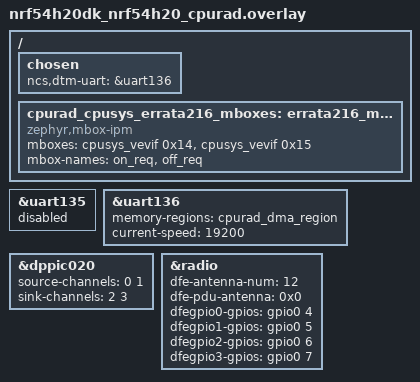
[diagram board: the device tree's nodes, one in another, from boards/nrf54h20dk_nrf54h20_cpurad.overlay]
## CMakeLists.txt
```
#
# Copyright (c) 2020 Nordic Semiconductor
#
# SPDX-License-Identifier: LicenseRef-Nordic-5-Clause
#
cmake_minimum_required(VERSION 3.20.0)

find_package(Zephyr REQUIRED HINTS $ENV{ZEPHYR_BASE})
project(NONE)

target_include_directories(app PRIVATE ./src)

target_sources_ifndef(CONFIG_DTM_TRANSPORT_HCI app PRIVATE
  src/transport/dtm_uart_twowire.c
  src/transport/dtm_uart_wait.c
)

target_sources_ifdef(CONFIG_DTM_TRANSPORT_HCI app PRIVATE src/transport/dtm_hci.c)

if(CONFIG_DTM_TRANSPORT_HCI AND "${BOARD}" STREQUAL "nrf5340dk")
  target_sources(app PRIVATE src/transport/hci_uart_remote.c)
  target_include_directories(app PRIVATE ./rpc)
else()
  target_sources_ifdef(CONFIG_DTM_TRANSPORT_HCI app PRIVATE src/transport/hci_uart.c)
endif()

# NORDIC SDK APP START
target_sources(app PRIVATE
  src/dtm.c
  src/dtm_hw.c
  src/main.c
)
# NORDIC SDK APP END
```

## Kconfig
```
#
# Copyright (c) 2020 Nordic Semiconductor
#
# SPDX-License-Identifier: LicenseRef-Nordic-5-Clause
#

mainmenu "Nordic DTM sample"

config DTM_RADIO_IRQ_PRIORITY
	int "Radio interrupt priority"
	range 0 5 if ZERO_LATENCY_IRQS
	range 0 6
	default 2
	help
	  Sets Radio interrupt priority.
	  Levels are from 0 (highest priority) to 6 (lowest priority)

config DTM_TIMER_IRQ_PRIORITY
	int "DTM timer interrupt priority"
	range 0 5 if ZERO_LATENCY_IRQS
	range 0 6
	default 3
	help
	  Sets DTM timer interrupt priority.
	  Levels are from 0 (highest priority) to 6 (lowest priority)

config ANOMALY_172_TIMER_IRQ_PRIORITY
	int "Anomaly 172 timer interrupt priority"
	depends on SOC_NRF52840
	range 0 5 if ZERO_LATENCY_IRQS
	range 0 6
	default 2
	help
	  Sets anomaly 172 timer interrupt priority.
	  Levels are from 0 (highest priority) to 6 (lowest priority)

config DTM_USB
	bool "DTM over USB CDC ACM class"
	depends on SOC_NRF5340_CPUNET && !DTM_TRANSPORT_HCI
	select EXPERIMENTAL
	help
	  Use USB instead of UART as the DTM interface. For nRF5340 the USB from application core
	  is used as communication interface.

config DTM_TRANSPORT_HCI
	bool "DTM over HCI UART [EXPERIMENTAL]"
	depends on SERIAL
	depends on NET_BUF
	select EXPERIMENTAL
	help
	  Use the HCI UART transport interface as the DTM transport layer.
	  This option is inherited from SB_CONFIG_DTM_TRANSPORT_HCI.

if DTM_TRANSPORT_HCI

config DTM_HCI_QUEUE_COUNT
	int "Count of HCI RX/TX queues"
	default 16
	help
	  Maximum depth of the HCI RX/TX queues.

config DTM_HCI_QUEUE_SIZE
	int "Size of HCI RX/TX queue buffer"
	default 1024
	help
	  Maximum size of the HCI RX/TX queue element.

config DTM_HCI_TX_THREAD_STACK_SIZE
	int "Stack size of TX thread"
	default 2048
	help
	  Stack size of the TX thread.

config DTM_HCI_TX_THREAD_PRIORITY
	int "TX thread priority"
	default 7
	help
	  Priority of the TX thread.

endif # DTM_TRANSPORT_HCI

config DTM_POWER_CONTROL_AUTOMATIC
	bool "Automatic power control"
	depends on FEM
	default y
	help
	  Set the SoC output power and the front-end module gain to achieve the TX output power
	  requested by user. If the exact value cannot be achieved, power is set to the closest
	  possible value. If this option is disabled, user can set the SoC output power and the
	  front-end module gain with the separate vendor specific commands.

config DTM_FAST_RAMP_UP
	bool "Enable radio fast ramp up mode"
	default y
	help
	  Do fast ramp up when starting the radio peripheral. This mode will significancy reduce
	  the ramp up time and makes it almost the same on all supported chips.

module = DTM_TRANSPORT
module-str = "DTM_transport"
source "${ZEPHYR_BASE}/subsys/logging/Kconfig.template.log_config"

source "Kconfig.zephyr"
```

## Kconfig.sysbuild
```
#
# Copyright (c) 2024 Nordic Semiconductor
#
# SPDX-License-Identifier: LicenseRef-Nordic-5-Clause
#

choice APPCORE
	default APPCORE_REMOTE_HCI if DTM_TRANSPORT_HCI
	default APPCORE_REMOTE_SHELL if SOC_NRF5340_CPUNET
	depends on SUPPORT_APPCORE

config APPCORE_REMOTE_HCI
	bool "remote_hci"
	depends on SOC_NRF5340_CPUNET
	help
	  Include remote_hci as the appcore image to use

endchoice

config APPCORE_IMAGE_NAME
	default "remote_hci" if APPCORE_REMOTE_HCI

config APPCORE_IMAGE_PATH
	default "${ZEPHYR_NRF_MODULE_DIR}/samples/bluetooth/direct_test_mode/remote_hci" if APPCORE_REMOTE_HCI

choice DTM_TRANSPORT
	default DTM_TRANSPORT_TWOWIRE
	prompt "Transport layer to use with DTM"
	help
	  Transport interface to use with the DTM.

config DTM_TRANSPORT_TWOWIRE
	bool "DTM over 2-wire UART"
	help
	  Use the 2-wire transport interface as the DTM transport layer.

config DTM_TRANSPORT_HCI
	bool "DTM over HCI UART [EXPERIMENTAL]"
	select EXPERIMENTAL
	help
	  Use the HCI UART transport interface as the DTM transport layer.

endchoice # DTM_TRANSPORT

config DTM_NO_DFE
	bool "Disable direction finding"
	help
	  Disable direction finding feature.

source "share/sysbuild/Kconfig"
```

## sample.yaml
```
sample:
  description: Bluetooth Low Energy Direct Test Mode sample
  name: Bluetooth LE Direct Test Mode
tests:
  sample.bluetooth.direct_test_mode:
    sysbuild: true
    build_only: true
    integration_platforms:
      - nrf5340dk/nrf5340/cpunet
      - nrf21540dk/nrf52840
      - nrf52840dk/nrf52840
      - nrf54l15dk/nrf54l05/cpuapp
      - nrf54l15dk/nrf54l10/cpuapp
      - nrf54l15dk/nrf54l15/cpuapp
      - nrf54lm20pdk/nrf54lm20a/cpuapp
      - nrf54lv10dk/nrf54lv10a/cpuapp
      - nrf54h20dk/nrf54h20/cpurad
    platform_allow:
      - nrf5340dk/nrf5340/cpunet
      - nrf21540dk/nrf52840
      - nrf52840dk/nrf52840
      - nrf54l15dk/nrf54l05/cpuapp
      - nrf54l15dk/nrf54l10/cpuapp
      - nrf54l15dk/nrf54l15/cpuapp
      - nrf54lm20pdk/nrf54lm20a/cpuapp
      - nrf54lv10dk/nrf54lv10a/cpuapp
      - nrf54h20dk/nrf54h20/cpurad
    tags:
      - bluetooth
      - ci_build
      - sysbuild
  sample.bluetooth.direct_test_mode.hci:
    sysbuild: true
    build_only: true
    extra_args: FILE_SUFFIX=hci
    integration_platforms:
      - nrf5340dk/nrf5340/cpunet
      - nrf21540dk/nrf52840
      - nrf52840dk/nrf52840
      - nrf54l15dk/nrf54l15/cpuapp
      - nrf54h20dk/nrf54h20/cpurad
    platform_allow:
      - nrf5340dk/nrf5340/cpunet
      - nrf21540dk/nrf52840
      - nrf52840dk/nrf52840
      - nrf54l15dk/nrf54l15/cpuapp
      - nrf54h20dk/nrf54h20/cpurad
    tags:
      - bluetooth
      - ci_build
      - sysbuild
  sample.bluetooth.direct_test_mode.nrf5340_nrf21540:
    sysbuild: true
    build_only: true
    extra_args: SHIELD=nrf21540ek
    integration_platforms:
      - nrf5340dk/nrf5340/cpunet
    platform_allow: nrf5340dk/nrf5340/cpunet
    tags:
      - bluetooth
      - ci_build
      - sysbuild
  sample.bluetooth.direct_test_mode.nrf5340_usb:
    sysbuild: true
    build_only: true
    extra_args: FILE_SUFFIX=usb
    integration_platforms:
      - nrf5340dk/nrf5340/cpunet
    platform_allow: nrf5340dk/nrf5340/cpunet
    tags:
      - bluetooth
      - ci_build
      - sysbuild
  sample.bluetooth.direct_test_mode.nrf5340_nrf21540_usb:
    sysbuild: true
    build_only: true
    extra_args:
      - SHIELD=nrf21540ek
      - FILE_SUFFIX=usb
    integration_platforms:
      - nrf5340dk/nrf5340/cpunet
    platform_allow: nrf5340dk/nrf5340/cpunet
    tags:
      - bluetooth
      - ci_build
      - sysbuild
  sample.bluetooth.direct_test_mode.nrf5340_nrf21540.no_automatic_power:
    sysbuild: true
    build_only: true
    extra_args: SHIELD=nrf21540ek
    extra_configs:
      - CONFIG_DTM_POWER_CONTROL_AUTOMATIC=n
    integration_platforms:
      - nrf5340dk/nrf5340/cpunet
    platform_allow: nrf5340dk/nrf5340/cpunet
    tags:
      - bluetooth
      - ci_build
      - sysbuild
  sample.bluetooth.direct_test_mode.nrf5340_no_dfe:
    sysbuild: true
    build_only: true
    extra_args: DSB_CONFIG_DTM_NO_DFE=y
    integration_platforms:
      - nrf5340dk/nrf5340/cpunet
    platform_allow: nrf5340dk/nrf5340/cpunet
    tags:
      - bluetooth
      - ci_build
      - sysbuild
  sample.bluetooth.direct_test_mode.nrf2220:
    sysbuild: true
    build_only: true
    extra_args: SHIELD=nrf2220ek
    integration_platforms:
      - nrf5340dk/nrf5340/cpunet
      - nrf54l15dk/nrf54l15/cpuapp
    platform_allow:
      - nrf5340dk/nrf5340/cpunet
      - nrf54l15dk/nrf54l15/cpuapp
    tags:
      - bluetooth
      - ci_build
      - sysbuild
  sample.bluetooth.direct_test_mode.nrf5340_nrf2220_usb:
    sysbuild: true
    build_only: true
    extra_args:
      - SHIELD=nrf2220ek
      - FILE_SUFFIX=usb
    integration_platforms:
      - nrf5340dk/nrf5340/cpunet
    platform_allow: nrf5340dk/nrf5340/cpunet
    tags:
      - bluetooth
      - ci_build
      - sysbuild
```

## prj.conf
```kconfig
#
# Copyright (c) 2020 Nordic Semiconductor
#
# SPDX-License-Identifier: LicenseRef-Nordic-5-Clause
#

# Configure assertions
CONFIG_ASSERT=y
CONFIG_ASSERT_NO_COND_INFO=y
CONFIG_ASSERT_NO_MSG_INFO=y

CONFIG_HW_STACK_PROTECTION=y

CONFIG_CONSOLE=n
CONFIG_UART_CONSOLE=n

CONFIG_LOG=y
CONFIG_LOG_PRINTK=y
CONFIG_USE_SEGGER_RTT=y
CONFIG_LOG_BACKEND_RTT=y

# Use necessary peripherals
CONFIG_NRFX_TIMER0=y
CONFIG_NRFX_TIMER1=y
CONFIG_NRFX_TIMER2=y
CONFIG_NRFX_GPPI=y
CONFIG_CLOCK_CONTROL=y

CONFIG_FEM_AL_LIB=y
```

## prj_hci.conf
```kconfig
#
# Copyright (c) 2020 Nordic Semiconductor
#
# SPDX-License-Identifier: LicenseRef-Nordic-5-Clause
#

# Configure assertions
CONFIG_ASSERT=y
CONFIG_ASSERT_NO_COND_INFO=y
CONFIG_ASSERT_NO_MSG_INFO=y

CONFIG_HW_STACK_PROTECTION=y

CONFIG_CONSOLE=n
CONFIG_UART_CONSOLE=n

CONFIG_LOG=y
CONFIG_LOG_PRINTK=y
CONFIG_USE_SEGGER_RTT=y
CONFIG_LOG_BACKEND_RTT=y

# Use necessary peripherals
CONFIG_NRFX_TIMER0=y
CONFIG_NRFX_TIMER1=y
CONFIG_NRFX_TIMER2=y
CONFIG_NRFX_GPPI=y
CONFIG_CLOCK_CONTROL=y

CONFIG_FEM_AL_LIB=y

CONFIG_DTM_TRANSPORT_HCI=y
CONFIG_NET_BUF=y
CONFIG_UART_ASYNC_API=y
```

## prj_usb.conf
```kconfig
#
# Copyright (c) 2020 Nordic Semiconductor
#
# SPDX-License-Identifier: LicenseRef-Nordic-5-Clause
#

# Configure assertions
CONFIG_ASSERT=y
CONFIG_ASSERT_NO_COND_INFO=y
CONFIG_ASSERT_NO_MSG_INFO=y

CONFIG_HW_STACK_PROTECTION=y

CONFIG_CONSOLE=n
CONFIG_UART_CONSOLE=n

CONFIG_LOG=y
CONFIG_LOG_PRINTK=y
CONFIG_USE_SEGGER_RTT=y
CONFIG_LOG_BACKEND_RTT=y

# Use necessary peripherals
CONFIG_NRFX_TIMER0=y
CONFIG_NRFX_TIMER1=y
CONFIG_NRFX_TIMER2=y
CONFIG_NRFX_GPPI=y
CONFIG_CLOCK_CONTROL=y

CONFIG_FEM_AL_LIB=y

CONFIG_DTM_USB=y
```

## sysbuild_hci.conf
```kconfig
#
# Copyright (c) 2024 Nordic Semiconductor
#
# SPDX-License-Identifier: LicenseRef-Nordic-5-Clause
#

SB_CONFIG_PARTITION_MANAGER=n
SB_CONFIG_DTM_TRANSPORT_HCI=y
```

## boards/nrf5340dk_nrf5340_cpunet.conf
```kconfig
#
# Copyright (c) 2021 Nordic Semiconductor
#
# SPDX-License-Identifier: LicenseRef-Nordic-5-Clause
#

CONFIG_IPC_UART=y
CONFIG_IPC_SERVICE=y
CONFIG_IPC_SERVICE_BACKEND_RPMSG=y
CONFIG_MBOX=y

CONFIG_HEAP_MEM_POOL_SIZE=4096
```

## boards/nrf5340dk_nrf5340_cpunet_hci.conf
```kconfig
#
# Copyright (c) 2021 Nordic Semiconductor
#
# SPDX-License-Identifier: LicenseRef-Nordic-5-Clause
#

CONFIG_IPC_SERVICE=y
CONFIG_IPC_SERVICE_BACKEND_RPMSG=y
CONFIG_MBOX=y

CONFIG_HEAP_MEM_POOL_SIZE=4096

CONFIG_NRF_RPC=y
CONFIG_NRF_RPC_CBOR=y

CONFIG_NET_BUF=y
```

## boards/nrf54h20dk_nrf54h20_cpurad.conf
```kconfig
#
# Copyright (c) 2024 Nordic Semiconductor
#
# SPDX-License-Identifier: LicenseRef-Nordic-5-Clause
#

# Disable the unsupported driver
CONFIG_NRFX_TIMER0=n
CONFIG_NRFX_TIMER1=n
CONFIG_NRFX_TIMER2=n

# Use necessary peripherals
CONFIG_NRFX_TIMER020=y
CONFIG_NRFX_TIMER021=y

CONFIG_MAIN_STACK_SIZE=2048
CONFIG_SYSTEM_WORKQUEUE_STACK_SIZE=2048
```

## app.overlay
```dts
/ {
	chosen {
		ncs,dtm-uart = &uart0;
	};
};

&uart0 {
	status = "okay";
	current-speed = <19200>;
};
```

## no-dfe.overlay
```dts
/*
 * Copyright (c) 2023 Nordic Semiconductor ASA
 *
 * SPDX-License-Identifier: LicenseRef-Nordic-5-Clause
 */

&radio {
	/delete-property/ dfe-supported;
};
```

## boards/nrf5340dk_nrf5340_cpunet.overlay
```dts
/*
 * Copyright (c) 2023 Nordic Semiconductor ASA
 *
 * SPDX-License-Identifier: LicenseRef-Nordic-5-Clause
 */

/ {
	chosen {
		ncs,dtm-uart = &uart_ipc;
	};

	uart_ipc: uart_ipc {
		status = "okay";
		compatible = "nordic,nrf-ipc-uart";
		ipc = <&ipc0>;
		ept-name = "remote shell";
		current-speed = <19200>;
	};
};

&radio {
	status = "okay";
	/* This is a number of antennas that are available on antenna matrix
	 * designed by Nordic. For more information see README.rst.
	 */
	dfe-antenna-num = <12>;
	/* This is a setting that enables antenna 12 (in antenna matrix designed
	 * by Nordic) for PDU. For more information see README.rst.
	 */
	dfe-pdu-antenna = <0x0>;

	/* These are GPIO pin numbers that are provided to
	 * Radio peripheral. The pins will be acquired by Radio to
	 * drive antenna switching.
	 * Pin numbers are selected to drive switches on antenna matrix
	 * desinged by Nordic. For more information see README.rst.
	 */
	dfegpio0-gpios = <&gpio0 4 0>;
	dfegpio1-gpios = <&gpio0 5 0>;
	dfegpio2-gpios = <&gpio0 6 0>;
	dfegpio3-gpios = <&gpio0 7 0>;
};
```

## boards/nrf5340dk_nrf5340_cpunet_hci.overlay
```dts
/*
 * Copyright (c) 2023 Nordic Semiconductor ASA
 *
 * SPDX-License-Identifier: LicenseRef-Nordic-5-Clause
 */

&radio {
	status = "okay";
	/* This is a number of antennas that are available on antenna matrix
	 * designed by Nordic. For more information see README.rst.
	 */
	dfe-antenna-num = <12>;
	/* This is a setting that enables antenna 12 (in antenna matrix designed
	 * by Nordic) for PDU. For more information see README.rst.
	 */
	dfe-pdu-antenna = <0x0>;

	/* These are GPIO pin numbers that are provided to
	 * Radio peripheral. The pins will be acquired by Radio to
	 * drive antenna switching.
	 * Pin numbers are selected to drive switches on antenna matrix
	 * desinged by Nordic. For more information see README.rst.
	 */
	dfegpio0-gpios = <&gpio0 4 0>;
	dfegpio1-gpios = <&gpio0 5 0>;
	dfegpio2-gpios = <&gpio0 6 0>;
	dfegpio3-gpios = <&gpio0 7 0>;
};
```

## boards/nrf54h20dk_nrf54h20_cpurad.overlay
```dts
/*
 * Copyright (c) 2024 Nordic Semiconductor ASA
 *
 * SPDX-License-Identifier: LicenseRef-Nordic-5-Clause
 */

 / {
	chosen {
		ncs,dtm-uart = &uart136;
	};
};

&uart135 {
	status = "disabled";
};

&uart136 {
	status = "okay";
	memory-regions = <&cpurad_dma_region>;
	current-speed = <19200>;
};

&dppic020 {
	status = "okay";
	source-channels = < 0 1 >;
	sink-channels = < 2 3 >;
};

&radio {
	status = "okay";
	/* This is a number of antennas that are available on antenna matrix
	 * designed by Nordic. For more information see README.rst.
	 */
	dfe-antenna-num = <12>;
	/* This is a setting that enables antenna 12 (in antenna matrix designed
	 * by Nordic) for PDU. For more information see README.rst.
	 */
	dfe-pdu-antenna = <0x0>;

	/* These are GPIO pin numbers that are provided to
	 * Radio peripheral. The pins will be acquired by Radio to
	 * drive antenna switching.
	 * Pin numbers are selected to drive switches on antenna matrix
	 * desinged by Nordic. For more information see README.rst.
	 */
	dfegpio0-gpios = <&gpio0 4 0>;
	dfegpio1-gpios = <&gpio0 5 0>;
	dfegpio2-gpios = <&gpio0 6 0>;
	dfegpio3-gpios = <&gpio0 7 0>;
};

/ {
	cpurad_cpusys_errata216_mboxes: errata216_mboxes {
		compatible = "zephyr,mbox-ipm";
		status = "okay";
		mboxes = < &cpusys_vevif 0x14 >, < &cpusys_vevif 0x15 >;
		mbox-names = "on_req", "off_req";
	};
};
```

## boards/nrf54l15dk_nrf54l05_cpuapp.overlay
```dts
/*
 * Copyright (c) 2024 Nordic Semiconductor ASA
 *
 * SPDX-License-Identifier: LicenseRef-Nordic-5-Clause
 */

/ {
	chosen {
		ncs,dtm-uart = &uart20;
	};
};

&uart20 {
	status = "okay";
	current-speed = <19200>;
};

&radio {
	status = "okay";
	/* This is a number of antennas that are available on antenna matrix
	 * designed by Nordic. For more information see README.rst.
	 */
	dfe-antenna-num = <12>;
	/* This is a setting that enables antenna 12 (in antenna matrix designed
	 * by Nordic) for PDU. For more information see README.rst.
	 */
	dfe-pdu-antenna = <0x0>;

	/* These are GPIO pin numbers that are provided to
	 * Radio peripheral. The pins will be acquired by Radio to
	 * drive antenna switching.
	 * Pin numbers are selected to drive switches on antenna matrix
	 * desinged by Nordic. For more information see README.rst.
	 */
	dfegpio0-gpios = <&gpio0 4 0>;
	dfegpio1-gpios = <&gpio0 5 0>;
	dfegpio2-gpios = <&gpio0 6 0>;
	dfegpio3-gpios = <&gpio0 7 0>;
};
```

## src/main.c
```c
/*
 * Copyright (c) 2020 Nordic Semiconductor ASA
 *
 * SPDX-License-Identifier: LicenseRef-Nordic-5-Clause
 */

#include <zephyr/device.h>
#include <zephyr/sys/printk.h>

#include "transport/dtm_transport.h"

int main(void)
{
	int err;
	union dtm_tr_packet cmd;

	printk("Starting Direct Test Mode sample\n");

	err = dtm_tr_init();
	if (err) {
		printk("Error initializing DTM transport: %d\n", err);
		return err;
	}

	for (;;) {
		cmd = dtm_tr_get();
		err = dtm_tr_process(cmd);
		if (err) {
			printk("Error processing command: %d\n", err);
			return err;
		}
	}
}
```

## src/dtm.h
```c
/*
 * Copyright (c) 2020 Nordic Semiconductor ASA
 *
 * SPDX-License-Identifier: LicenseRef-Nordic-5-Clause
 */

#ifndef DTM_H_
#define DTM_H_

#include <stdbool.h>
#include <zephyr/types.h>
#include <zephyr/devicetree.h>

#ifdef __cplusplus
extern "C" {
#endif

#define NRF_IQ_SAMPLE_INVALID -32768

/** @brief DTM PHY mode */
enum dtm_phy {
	/** Bluetooth Low Energy 1 Mbps PHY. */
	DTM_PHY_1M,

	/** Bluetooth Low Energy 2 Mbps PHY. */
	DTM_PHY_2M,

	/** Bluetooth Low Energy Coded S=8 PHY. */
	DTM_PHY_CODED_S8,

	/** Bluetooth Low Energy Coded S=2 PHY. */
	DTM_PHY_CODED_S2
};

/** @brief DTM modulation index. */
enum dtm_modulation {
	/** Standard modulation index. */
	DTM_MODULATION_STANDARD,

	/** Stable modulation index. */
	DTM_MODULATION_STABLE
};

/** @brief DTM maximum supported values. */
enum dtm_max_supported {
	/** Maximum supported TX octets. */
	DTM_MAX_SUPPORTED_TX_OCTETS,

	/** Maximum supported TX time. */
	DTM_MAX_SUPPORTED_TX_TIME,

	/** Maximum supported RX octets. */
	DTM_MAX_SUPPORTED_RX_OCTETS,

	/** Maximum supported RX time. */
	DTM_MAX_SUPPORTED_RX_TIME,

	/** Maximum supported Constant Tone Extension length. */
	DTM_MAX_SUPPORTED_CTE_LENGTH
};

/** @brief Constant Tone Extension type. */
enum dtm_cte_type {
	/** Do not use Constant Tone Extension. */
	DTM_CTE_TYPE_NONE,

	/** Angle of Arrival. */
	DTM_CTE_TYPE_AOA,

	/** Angle of Departure 1 us slots. */
	DTM_CTE_TYPE_AOD_1US,

	/** Angle of Departure 2 us slots. */
	DTM_CTE_TYPE_AOD_2US
};

/** @brief DTM Constant Tone Extension slot duration. */
enum dtm_cte_slot_duration {
	/** CTE 1 us slots duration. */
	DTM_CTE_SLOT_DURATION_1US,

	/** CTE 2 us slots duration. */
	DTM_CTE_SLOT_DURATION_2US
};

/** @brief DTM transmit power request. */
enum dtm_tx_power_request {
	/** Request minimum power. */
	DTM_TX_POWER_REQUEST_MIN,

	/** Request maximum power. */
	DTM_TX_POWER_REQUEST_MAX,

	/** Request power by value. */
	DTM_TX_POWER_REQUEST_VAL
};

/** @brief DTM packet type. */
enum dtm_packet {
	/** Packet filled with PRBS9 stream as payload. */
	DTM_PACKET_PRBS9,

	/** Packet with 0x0F bytes as payload. */
	DTM_PACKET_0F,

	/** Packet with 0x55 bytes as payload. */
	DTM_PACKET_55,

	/** Packet filled with PRBS15 stream as payload. */
	DTM_PACKET_PRBS15,

	/** Packet with 0xFF bytes as payload or vendor specific packet. */
	DTM_PACKET_FF_OR_VENDOR,

	/** Packet with 0xFF bytes as payload. */
	DTM_PACKET_FF,

	/** Packet with 0x00 bytes as payload. */
	DTM_PACKET_00,

	/** Packet with 0xF0 bytes as payload. */
	DTM_PACKET_F0,

	/** Packet with 0xAA bytes as payload. */
	DTM_PACKET_AA,

	/** Vendor-specific packet. */
	DTM_PACKET_VENDOR
};

/** @brief DTM supported features. */
struct dtm_supp_features {
	/** Support for Data Packet Length Extension. */
	bool data_len_ext;

	/** Support for Bluetooth Low Energy 2 Mbps PHY. */
	bool phy_2m;

	/** Support for Stable Modulation Index. */
	bool stable_mod;

	/** Support for Bluetooth Low Energy Coded PHY. */
	bool coded_phy;

	/** Support for Constant Tone Extension. */
	bool cte;

	/** Support for Antenna switching. */
	bool ant_switching;

	/** Support for AoD transmission 1 us switching. */
	bool aod_1us_tx;

	/** Support for AoD reception 1 us switching. */
	bool aod_1us_rx;

	/** Support for AoA reception 1 us switching and sampling. */
	bool aoa_1us_rx;
};

/** @brief DTM transmit power. */
struct dtm_tx_power {
	/** Actual power in dBm. */
	int8_t power;

	/** Power at minimum level. */
	bool min;

	/** Power at maximum level. */
	bool max;
};

/** @brief DTM Packet status for IQ Sample report. */
enum dtm_packet_status {
	/** Packet received with proper CRC. */
	DTM_PACKET_STATUS_CRC_OK,

	/** Packet received with invalid CRC.
	 *  The Length and CTEInfo was used to calculate sampling points.
	 */
	DTM_PACKET_STATUS_CRC_ERR_TIME,

	/** Packet received with invalid CRC.
	 *  The sampling points were calculated in another way.
	 */
	DTM_PACKET_STATUS_CRC_ERR_OTHER,

	/** Packet received with invalid CRC.
	 *  Insufficient resources to sample.
	 */
	DTM_PACKET_STATUS_CRC_ERR_INSUFFICIENT
};

/** @brief IQ sample format. */
struct dtm_iq_sample {
	/** I sample value. */
	int16_t i;

	/** Q sample value. */
	int16_t q;
};

/** @brief DTM IQ sampling data with additional information. */
struct dtm_iq_data {
	/** Channel number. */
	uint8_t channel;

	/** RSSI value of received packet. */
	int16_t rssi;

	/** Antenna number used to measure RSSI. */
	uint8_t rssi_ant;

	/** CTE type. */
	enum dtm_cte_type type;

	/** CTE slot duration. */
	enum dtm_cte_slot_duration slot;

	/** Packet status. */
	enum dtm_packet_status status;

	/** IQ sample count. */
	uint8_t sample_cnt;

	/** IQ samples. */
	struct dtm_iq_sample *samples;
};

/** @brief Callback to report received IQ samples.
 *
 * @note The callback is used only with direction finding.
 *
 * @param[in] data Pointer to dtm_iq_data structure.
 */
typedef void (*dtm_iq_report_callback_t)(struct dtm_iq_data *data);

/** @brief Initialize the DTM module.
 *
 * This function initializes the DTM module and registers the IQ sampling callback.
 * If the callback is not needed, the pointer can be NULL.
 *
 * @param[in] iq_callback Function pointer to the IQ report callback, can be NULL.
 *
 * @return 0 in case of success or negative value in case of error.
 */
int dtm_init(dtm_iq_report_callback_t callback);

/** @brief Prepare DTM for setup.
 *
 * @note This function should be called before setup functions.
 * The function can be called once before a block of setup functions.
 */
void dtm_setup_prepare(void);

/** @brief Reset the DTM state.
 *
 * The PHY is set to Bluetooth Low Energy 1M mode.
 * The modulation index is set to standard.
 * The CTE is turned off.
 *
 * @return 0 in case of success or negative value in case of error.
 */
int dtm_setup_reset(void);

/** @brief Set the PHY for DTM.
 *
 * @param[in] phy The PHY to be used.
 *
 * @return 0 in case of success or negative value in case of error.
 */
int dtm_setup_set_phy(enum dtm_phy phy);

/** @brief Set the modulation for DTM.
 *
 * @param[in] modulation The modulation to be used.
 *
 * @return 0 in case of success or negative value in case of error.
 */
int dtm_setup_set_modulation(enum dtm_modulation modulation);

/** @brief Read supported BLE features.
 *
 * @return Features supported by the device.
 */
struct dtm_supp_features dtm_setup_read_features(void);

/** @brief Read the maximum supported parameter value by DTM.
 *
 * @param[in] parameter Value to be read.
 * @param[out] max_val  The pointer to the maximum value.
 *
 * @return 0 in case of success or negative value in case of error.
 */
int dtm_setup_read_max_supported_value(enum dtm_max_supported parameter, uint16_t *max_val);

/** @brief Setup the CTE for DTM.
 *
 * @param[in] type The CTE type to be used.
 * @param[in] time The time of CTE in 8 us units.
 *
 * @return 0 in case of success or negative value in case of error.
 */
int dtm_setup_set_cte_mode(enum dtm_cte_type type, uint8_t time);

/** @brief Set the CTE slots duration for DTM.
 *
 * @param[in] slot The CTE slots duration.
 *
 * @return 0 in case of success or negative value in case of error.
 */
int dtm_setup_set_cte_slot(enum dtm_cte_slot_duration slot);

/** @brief Set the antenna parameters for DTM.
 *
 * @param[in] count       The antenna count.
 * @param[in] pattern     The antenna switching pattern.
 * @param[in] pattern_len The length of the pattern.
 *
 * @return 0 in case of success or negative value in case of error.
 */
int dtm_setup_set_antenna_params(uint8_t count, uint8_t *pattern, uint8_t pattern_len);

/** @brief Set the transmit power for DTM.
 *
 * @param[in] power   The transmit power request.
 * @param[in] val     TX power value (in dBm) in case of DTM_TX_POWER_REQUEST_VAL request.
 * @param[in] channel The channel to adjust power (set to 0 if unknown).
 *
 * @return The actual TX power set by the function.
 */
struct dtm_tx_power dtm_setup_set_transmit_power(enum dtm_tx_power_request power, int8_t val,
						 uint8_t channel);

/** @brief Start the DTM reception test.
 *
 * @param[in] channel The reception channel.
 *
 * @return 0 in case of success or negative value in case of error.
 */
int dtm_test_receive(uint8_t channel);

/** @brief Start the DTM transmission test.
 *
 * @param[in] channel The transmission channel.
 * @param[in] length  The packet length.
 * @param[in] pkt     The packet type.
 *
 * @return 0 in case of success or negative value in case of error.
 */
int dtm_test_transmit(uint8_t channel, uint8_t length, enum dtm_packet pkt);

/** @brief Stop the DTM test.
 *
 * Stop current DTM test and return the number of received packets.
 *
 * @param[out] pack_cnt The pointer to the received packet count.
 *
 * @return 0 in case of success or negative value in case of error.
 */
int dtm_test_end(uint16_t *pack_cnt);

#ifdef __cplusplus
}
#endif

#endif /* DTM_H_ */
```

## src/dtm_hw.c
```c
/*
 * Copyright (c) 2020 Nordic Semiconductor ASA
 *
 * SPDX-License-Identifier: LicenseRef-Nordic-5-Clause
 */

#include "nrf.h"

#include "dtm_hw.h"
#include "dtm_hw_config.h"

/* All valid power levels (in dBm) supported by the SoC. */
const int8_t nrf_power_value[] = {
#if defined(RADIO_TXPOWER_TXPOWER_Neg100dBm)
	-100,
#endif /* defined(RADIO_TXPOWER_TXPOWER_Neg100dBm) */
#if defined(RADIO_TXPOWER_TXPOWER_Neg70dBm)
	-70,
#endif /* defined(RADIO_TXPOWER_TXPOWER_Neg70dBm) */
#if defined(RADIO_TXPOWER_TXPOWER_Neg46dBm)
	-46,
#endif /* defined(RADIO_TXPOWER_TXPOWER_Neg46dBm) */
#if defined(RADIO_TXPOWER_TXPOWER_Neg40dBm)
	-40,
#endif /* RADIO_TXPOWER_TXPOWER_Neg40dBm */
#if defined(RADIO_TXPOWER_TXPOWER_Neg30dBm)
	-30,
#endif /* defined(RADIO_TXPOWER_TXPOWER_Neg30dBm) */
#if defined(RADIO_TXPOWER_TXPOWER_Neg28dBm)
	-28,
#endif /* defined(RADIO_TXPOWER_TXPOWER_Neg28dBm) */
#if defined(RADIO_TXPOWER_TXPOWER_Neg22dBm)
	-22,
#endif /* defined(RADIO_TXPOWER_TXPOWER_Neg22dBm) */
	-20,
#if defined(RADIO_TXPOWER_TXPOWER_Neg18dBm)
	-18,
#endif /* defined(RADIO_TXPOWER_TXPOWER_Neg18dBm) */
	-16,
#if defined(RADIO_TXPOWER_TXPOWER_Neg14dBm)
	-14,
#endif /* defined(RADIO_TXPOWER_TXPOWER_Neg14dBm) */
	-12,
#if defined(RADIO_TXPOWER_TXPOWER_Neg10dBm)
	-10,
#endif /* defined(RADIO_TXPOWER_TXPOWER_Neg10dBm) */
#if defined(RADIO_TXPOWER_TXPOWER_Neg9dBm)
	-9,
#endif /* defined(RADIO_TXPOWER_TXPOWER_Neg9dBm) */
	-8,
#if defined(RADIO_TXPOWER_TXPOWER_Neg7dBm)
	-7,
#endif /* defined(RADIO_TXPOWER_TXPOWER_Neg7dBm) */
#if defined(RADIO_TXPOWER_TXPOWER_Neg6dBm)
	-6,
#endif /* defined(RADIO_TXPOWER_TXPOWER_Neg6dBm) */
#if defined(RADIO_TXPOWER_TXPOWER_Neg5dBm)
	-5,
#endif /* defined(RADIO_TXPOWER_TXPOWER_Neg5dBm) */
	-4,
#if defined(RADIO_TXPOWER_TXPOWER_Neg3dBm)
	-3,
#endif /* defined (RADIO_TXPOWER_TXPOWER_Neg3dBm) */
#if defined(RADIO_TXPOWER_TXPOWER_Neg2dBm)
	-2,
#endif /* defined (RADIO_TXPOWER_TXPOWER_Neg2dBm) */
#if defined(RADIO_TXPOWER_TXPOWER_Neg1dBm)
	-1,
#endif /* defined (RADIO_TXPOWER_TXPOWER_Neg1dBm) */
	0,
#if defined(RADIO_TXPOWER_TXPOWER_Pos1dBm)
	1,
#endif /* RADIO_TXPOWER_TXPOWER_Pos1dBm */
#if defined(RADIO_TXPOWER_TXPOWER_Pos2dBm)
	2,
#endif /* defined(RADIO_TXPOWER_TXPOWER_Pos2dBm) */
#if defined(RADIO_TXPOWER_TXPOWER_Pos3dBm)
	3,
#endif /* defined(RADIO_TXPOWER_TXPOWER_Pos3dBm) */
#if defined(RADIO_TXPOWER_TXPOWER_Pos4dBm)
	4,
#endif /* defined(RADIO_TXPOWER_TXPOWER_Pos4dBm) */
#if defined(RADIO_TXPOWER_TXPOWER_Pos5dBm)
	5,
#endif /* defined(RADIO_TXPOWER_TXPOWER_Pos5dBm) */
#if defined(RADIO_TXPOWER_TXPOWER_Pos6dBm)
	6,
#endif /* defined(RADIO_TXPOWER_TXPOWER_Pos6dBm) */
#if defined(RADIO_TXPOWER_TXPOWER_Pos7dBm)
	7,
#endif /* defined(RADIO_TXPOWER_TXPOWER_Pos7dBm) */
#if defined(RADIO_TXPOWER_TXPOWER_Pos8dBm)
	8,
#endif /* defined(RADIO_TXPOWER_TXPOWER_Pos8dBm) */
#if defined(RADIO_TXPOWER_TXPOWER_Pos9dBm)
	9,
#endif /* defined(RADIO_TXPOWER_TXPOWER_Pos9dBm) */
#if defined(RADIO_TXPOWER_TXPOWER_Pos10dBm)
	10
#endif /* defined(RADIO_TXPOWER_TXPOWER_Pos10dBm) */
};

#if DIRECTION_FINDING_SUPPORTED

#define DTM_MAX_ANTENNA_NUMBER 19

#define DFE_GPIO_PIN_DISCONNECT (RADIO_PSEL_DFEGPIO_CONNECT_Disconnected << \
				 RADIO_PSEL_DFEGPIO_CONNECT_Pos)

#define HAS_DFE_GPIO(idx) DT_NODE_HAS_PROP(RADIO_NODE, dfegpio##idx##_gpios)

/* Run a macro 'fn' on each available DFE GPIO index, from 0 to
 * MAX_DFE_GPIO-1, with the given parenthesized separator.
 */
#if DTM_HW_MAX_DFE_GPIO == 8
#define FOR_EACH_DFE_GPIO(fn, sep) FOR_EACH(fn, sep, 0, 1, 2, 3, 4, 5, 6, 7)
#elif DTM_HW_MAX_DFE_GPIO == 7
#define FOR_EACH_DFE_GPIO(fn, sep) FOR_EACH(fn, sep, 0, 1, 2, 3, 4, 5, 6)
#else
#error "Unsupported DFE GPIO count"
#endif

/* The number of dfegpio[n]-gpios properties which are set. */
#define DFE_GPIO_NUM (FOR_EACH_DFE_GPIO(HAS_DFE_GPIO, (+)))

#define PDU_ANTENNA DT_PROP(RADIO_NODE, dfe_pdu_antenna)

/* The minimum number of antennas required to enable antenna switching. */
#define MIN_ANTENNA_NUM 1

/* The maximum number of antennas supported by the number of
 * dfegpio[n]-gpios properties which are set.
 */
#if (DFE_GPIO_NUM > 0)
#define MAX_ANTENNA_NUM BIT(DFE_GPIO_NUM)
#else
#define MAX_ANTENNA_NUM 0
#endif

/*
 * Check that the number of antennas has been set, and that enough
 * pins are configured to represent each pattern for the given number
 * of antennas.
 */
#define HAS_ANTENNA_NUM DT_NODE_HAS_PROP(RADIO_NODE, dfe_antenna_num)

BUILD_ASSERT(HAS_ANTENNA_NUM,
	     "You must set the dfe-antenna-num property in the radio node "
	     "to enable antenna switching.");

#define ANTENNA_NUM DT_PROP_OR(RADIO_NODE, dfe_antenna_num, 0)


BUILD_ASSERT(!HAS_ANTENNA_NUM || (ANTENNA_NUM <= MAX_ANTENNA_NUM),
	     "Insufficient number of GPIO pins configured. "
	     "Set more dfegpio[n]-gpios properties.");
BUILD_ASSERT(!HAS_ANTENNA_NUM || (ANTENNA_NUM >= MIN_ANTENNA_NUM),
	     "Insufficient number of antennas provided. "
	     "Increase the dfe-antenna-num property.");

#define HAS_PDU_ANTENNA DT_NODE_HAS_PROP(RADIO_NODE, dfe_pdu_antenna)

BUILD_ASSERT(HAS_PDU_ANTENNA,
	     "Missing antenna pattern used to select antenna for PDU Tx "
	     "during the CTE Idle state. "
	     "Set the dfe-pdu-antenna devicetree property.");

/*
 * Check that each dfegpio[n]-gpios property has a zero flags cell.
 */
#define ASSERT_DFE_GPIO_FLAGS_ARE_ZERO(idx)				   \
	BUILD_ASSERT(DT_GPIO_FLAGS(RADIO_NODE, dfegpio##idx##_gpios) == 0, \
		     "The flags cell in each dfegpio[n]-gpios "		   \
		     "property must be zero.")

FOR_EACH_DFE_GPIO(ASSERT_DFE_GPIO_FLAGS_ARE_ZERO, (;));

#define DFE_GPIO_PSEL(idx)					  \
	NRF_DT_GPIOS_TO_PSEL_OR(RADIO_NODE, dfegpio##idx##_gpios, \
				DTM_HW_DFE_PSEL_NOT_SET)

static const struct dtm_ant_cfg {
	uint8_t ant_num;
	/* Selection of GPIOs to be used to switch antennas by Radio */
	uint8_t dfe_gpio[DTM_HW_MAX_DFE_GPIO];
} ant_cfg = {
	.ant_num = (ANTENNA_NUM > DTM_MAX_ANTENNA_NUMBER) ? DTM_MAX_ANTENNA_NUMBER : ANTENNA_NUM,
	.dfe_gpio = { FOR_EACH_DFE_GPIO(DFE_GPIO_PSEL, (,)) }
};
#endif /* DIRECTION_FINDING_SUPPORTED */

bool dtm_hw_radio_validate(int8_t tx_power,
			   nrf_radio_mode_t radio_mode)
{
	/* Initializing code below is quite generic - for BLE, the values are
	 * fixed, and expressions are constant. Non-constant values are
	 * essentially set in radio_prepare().
	 */

	if (!(
#if CONFIG_HAS_HW_NRF_RADIO_BLE_CODED
		radio_mode == NRF_RADIO_MODE_BLE_LR125KBIT  ||
		radio_mode == NRF_RADIO_MODE_BLE_LR500KBIT  ||
#endif /* CONFIG_HAS_HW_NRF_RADIO_BLE_CODED */
		radio_mode == NRF_RADIO_MODE_BLE_1MBIT      ||
		radio_mode == NRF_RADIO_MODE_BLE_2MBIT
		)
	) {
		return false;
	}

	for (size_t i = 0; i < ARRAY_SIZE(nrf_power_value); i++) {
		if (tx_power == nrf_power_value[i]) {
			return true;
		}
	}

	return false;
}

bool dtm_hw_radio_lr_check(nrf_radio_mode_t radio_mode)
{
#if CONFIG_HAS_HW_NRF_RADIO_BLE_CODED
	if (radio_mode == NRF_RADIO_MODE_BLE_LR125KBIT) {
		return true;
	}

	if (radio_mode == NRF_RADIO_MODE_BLE_LR500KBIT) {
		return true;
	}
#endif /* CONFIG_HAS_HW_NRF_RADIO_BLE_CODED */

	return false;
}

uint32_t dtm_hw_radio_min_power_get(void)
{
	return nrf_power_value[0];
}

uint32_t dtm_hw_radio_max_power_get(void)
{
	return nrf_power_value[ARRAY_SIZE(nrf_power_value) - 1];
}

size_t dtm_hw_radio_power_array_size_get(void)
{
	return ARRAY_SIZE(nrf_power_value);
}

const int8_t *dtm_hw_radio_power_array_get(void)
{
	return nrf_power_value;
}

#if DIRECTION_FINDING_SUPPORTED
size_t dtm_hw_radio_antenna_number_get(void)
{
	return ant_cfg.ant_num;
}

const uint8_t *dtm_hw_radio_antenna_pin_array_get(void)
{
	return ant_cfg.dfe_gpio;
}

uint8_t dtm_hw_radio_pdu_antenna_get(void)
{
	return PDU_ANTENNA;
}
#endif /* DIRECTION_FINDING_SUPPORTED */
```

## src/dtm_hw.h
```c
/*
 * Copyright (c) 2020 Nordic Semiconductor ASA
 *
 * SPDX-License-Identifier: LicenseRef-Nordic-5-Clause
 */

#ifndef DTM_HW_H_
#define DTM_HW_H_

#include <stdbool.h>
#include <zephyr/types.h>

#include <hal/nrf_radio.h>

#ifdef __cplusplus
extern "C" {
#endif

/* Number of PSEL_DFEGPIO[n] registers in the radio peripheral. */
#if defined(RADIO_PSEL_DFEGPIO_MaxCount)
#define DTM_HW_MAX_DFE_GPIO RADIO_PSEL_DFEGPIO_MaxCount
#else
#define DTM_HW_MAX_DFE_GPIO 8
#endif

/* Indicates that GPIO pin is not connected to the radio */
#define DTM_HW_DFE_PSEL_NOT_SET 0xFF

/* Disconnect pin from the RADIO DFGPIO register. */
#define DTM_HW_DFE_GPIO_PIN_DISCONNECT (RADIO_PSEL_DFEGPIO_CONNECT_Disconnected << \
					RADIO_PSEL_DFEGPIO_CONNECT_Pos)

/**@brief Function for validating tx power and radio mode settings.
 * @param[in] tx_power    TX power for transmission test in dBm.
 * @param[in] radio_mode  Radio mode value.
 *
 * @retval true  If validation was successful
 * @retval false Otherwise
 */
bool dtm_hw_radio_validate(int8_t tx_power,
			   nrf_radio_mode_t radio_mode);

/**@brief Function for checking if Radio operates in Long Range mode.
 * @param[in] radio_mode  Radio mode value.
 *
 * @retval true  If Long Range Radio mode is set
 * @retval false Otherwise
 */
bool dtm_hw_radio_lr_check(nrf_radio_mode_t radio_mode);

/**@brief Function for getting minimum tx power.
 *
 * @retval Minimum tx power value.
 */
uint32_t dtm_hw_radio_min_power_get(void);

/**@brief Function for getting maximum tx power.
 *
 * @retval Maximum tx power value.
 */
uint32_t dtm_hw_radio_max_power_get(void);

/**@brief Function for getting power array size. This array contains all
 *        possible tx power values for given divice sorted in ascending
 *        order.
 *
 * @reval Size of the tx power array.
 */
size_t dtm_hw_radio_power_array_size_get(void);

/**@brief Function for getting tx power array. This array contains all
 *        possible tx power values for given divice sorted in ascending
 *        order.
 *
 * @retval Size of the tx power array.
 */
const int8_t *dtm_hw_radio_power_array_get(void);

/**@brief Function for getting antenna pins array. This array contains
 *        all antenna pins data.
 *
 * @retval Pointer to the first element in antenna pins array.
 */
const uint8_t *dtm_hw_radio_antenna_pin_array_get(void);

/**@brief Function for getting available antenna number.
 *
 * @retval Maximum antenna number that DTM can use.
 */
size_t dtm_hw_radio_antenna_number_get(void);

/**@brief Function for getting the PDU antenna.
 *
 * @retval The PDU antenna.
 */
uint8_t dtm_hw_radio_pdu_antenna_get(void);

#ifdef __cplusplus
}
#endif

#endif /* DTM_HW_H_ */
```

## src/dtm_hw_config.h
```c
/*
 * Copyright (c) 2020 Nordic Semiconductor ASA
 *
 * SPDX-License-Identifier: LicenseRef-Nordic-5-Clause
 */

#ifndef DTM_HW_CONFIG_H_
#define DTM_HW_CONFIG_H_

#ifdef __cplusplus
extern "C" {
#endif

/* Devicetree node identifier for the radio node. */
#define RADIO_NODE DT_NODELABEL(radio)

#if DT_PROP(DT_NODELABEL(radio), dfe_supported) && \
	DT_NODE_HAS_STATUS(RADIO_NODE, okay)
#define DIRECTION_FINDING_SUPPORTED 1
#else
#define DIRECTION_FINDING_SUPPORTED 0
#endif /* DT_PROP(DT_NODELABEL(radio), dfe_supported) && \
	* DT_NODE_HAS_STATUS(RADIO_NODE, okay)
	*/

/* Maximum transmit or receive time, in microseconds, that the local
 * Controller supports for transmission of a single
 * Link Layer Data Physical Channel PDU, divided by 2.
 */
#if defined(NRF52840_XXAA) || defined(NRF52833_XXAA) || \
	defined(NRF52811_XXAA) || defined(NRF52820_XXAA)
#define NRF_MAX_RX_TX_TIME 0x2148
#else
#define NRF_MAX_RX_TX_TIME 0x424
#endif /* defined(NRF52840_XXAA) || defined(NRF52833_XXAA) ||
	* defined(NRF52811_XXAA) || defined(NRF52820_XXAA)
	*/

#ifdef NRF53_SERIES
#ifndef RADIO_TXPOWER_TXPOWER_Pos3dBm
	#define RADIO_TXPOWER_TXPOWER_Pos3dBm (0x03UL)
#endif /* RADIO_TXPOWER_TXPOWER_Pos3dBm */

#ifndef RADIO_TXPOWER_TXPOWER_Pos2dBm
	#define RADIO_TXPOWER_TXPOWER_Pos2dBm (0x02UL)
#endif /* RADIO_TXPOWER_TXPOWER_Pos2dBm */

#ifndef RADIO_TXPOWER_TXPOWER_Pos1dBm
	#define RADIO_TXPOWER_TXPOWER_Pos1dBm (0x01UL)
#endif /* RADIO_TXPOWER_TXPOWER_Pos1dBm */
#endif /* NRF53_SERIES */

#ifdef __cplusplus
}
#endif

#endif /* DTM_HW_CONFIG_H_ */
```
